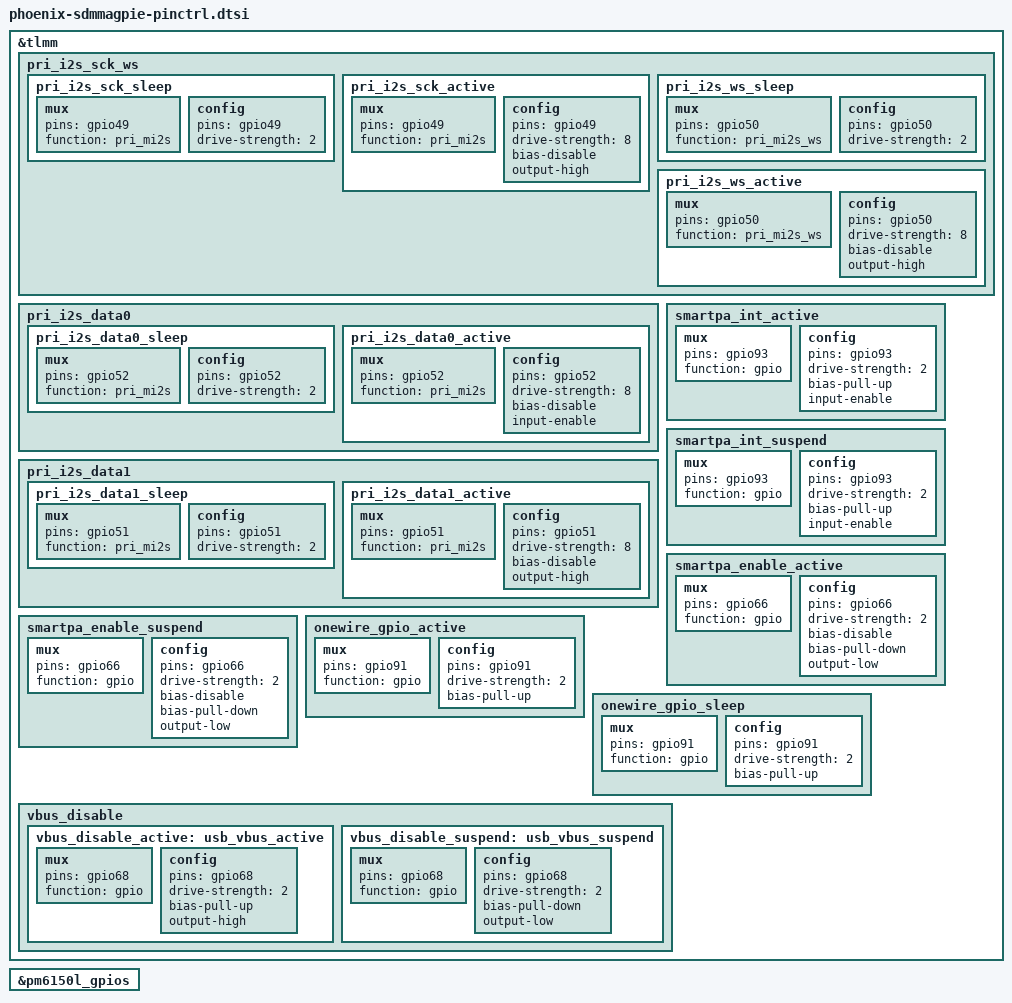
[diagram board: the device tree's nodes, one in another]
/*for G7B SM7150 pinctrl*/

&tlmm {

	pri_i2s_sck_ws {
		pri_i2s_sck_sleep: pri_i2s_sck_sleep {
			mux {
				pins = "gpio49";
				function = "pri_mi2s";
			};

			config {
				pins = "gpio49";
				drive-strength = <2>;   /* 2 mA */
			};
		};

		pri_i2s_sck_active: pri_i2s_sck_active {
			mux {
				pins = "gpio49";
				function = "pri_mi2s";
			};

			config {
				pins = "gpio49";
				drive-strength = <8>;   /* 8 mA */
				bias-disable;
				output-high;
			};
		};

		pri_i2s_ws_sleep: pri_i2s_ws_sleep {
			mux {
				pins = "gpio50";
				function = "pri_mi2s_ws";
			};

			config {
				pins = "gpio50";
				drive-strength = <2>;   /* 2 mA */
			};
		};

		pri_i2s_ws_active: pri_i2s_ws_active {
			mux {
				pins = "gpio50";
				function = "pri_mi2s_ws";
			};

			config {
				pins = "gpio50";
				drive-strength = <8>;   /* 8 mA */
				bias-disable;
				output-high;
			};
		};
	};

	pri_i2s_data0 {
		pri_i2s_data0_sleep: pri_i2s_data0_sleep {
			mux {
				pins = "gpio52";
				function = "pri_mi2s";
			};

			config {
				pins = "gpio52";
				drive-strength = <2>;   /* 2 mA */
			};
		};

		pri_i2s_data0_active: pri_i2s_data0_active {
			mux {
				pins = "gpio52";
				function = "pri_mi2s";
			};

			config {
				pins = "gpio52";
				drive-strength = <8>;   /* 8 mA */
				bias-disable;
				input-enable;
			};
		};
	};

	pri_i2s_data1 {
		pri_i2s_data1_sleep: pri_i2s_data1_sleep {
			mux {
				pins = "gpio51";
				function = "pri_mi2s";
			};

			config {
				pins = "gpio51";
				drive-strength = <2>;   /* 2 mA */
			};
		};

		pri_i2s_data1_active: pri_i2s_data1_active {
			mux {
				pins = "gpio51";
				function = "pri_mi2s";
			};

			config {
				pins = "gpio51";
				drive-strength = <8>;   /* 8 mA */
				bias-disable;
				output-high;
			};
		};
	};

	smartpa_int_active: smartpa_int_active {
		/* active state */
		mux {
			/* GPIO 93 Interrupt */
			pins = "gpio93";
			function = "gpio";
		};

		config {
			pins = "gpio93";
			drive-strength = <2>; /* 2 MA */
			bias-pull-up;
			input-enable;
		};
	};

	smartpa_int_suspend: smartpa_int_suspend {
		/* sleep state */
		mux {
			/* GPIO 93 Interrupt */
			pins = "gpio93";
			function = "gpio";
		};

		config {
			pins = "gpio93";
			drive-strength = <2>; /* 2 MA */
			bias-pull-up;
			input-enable;
		};
	};

	smartpa_enable_active: smartpa_enable_active {
		/* active state */
		mux {
			/* GPIO 66 rst pin */
			pins = "gpio66";
			function = "gpio";
		};

		config {
			pins = "gpio66";
			drive-strength = <2>;
			bias-disable;
			bias-pull-down;
			output-low;
		};
	};

	smartpa_enable_suspend: smartpa_enable_suspend {
		/* sleep state */
		mux {
			/* GPIO 66 rst pin */
			pins = "gpio66";
			function = "gpio";
		};

		config {
			pins = "gpio66";
			drive-strength = <2>;
			bias-disable;
			bias-pull-down;
			output-low;
		};
	};

	onewire_gpio_active: onewire_gpio_active {
		mux {
			pins = "gpio91";
			function = "gpio";
		};

		config {
			pins = "gpio91";
			drive-strength = <2>;
			bias-pull-up; /* No PULL */
		};
	};

	onewire_gpio_sleep: onewire_gpio_sleep {
		mux {
			pins = "gpio91";
			function = "gpio";
		};

		config {
			pins = "gpio91";
			drive-strength = <2>;
			bias-pull-up;
		};
	};

	vbus_disable {
		vbus_disable_active: usb_vbus_active {
			/* active state */
			mux {
				pins = "gpio68";
				function = "gpio";
			};

			config {
				pins = "gpio68";
				drive-strength = <2>; /* 2 MA */
				bias-pull-up;
				output-high;

			};
		};

		vbus_disable_suspend: usb_vbus_suspend {
			mux {
				pins = "gpio68";
				function = "gpio";
			};

			config {
				pins = "gpio68";
				drive-strength = <2>; /* 2 MA */
				bias-pull-down;
				output-low;
			};
		};
	};

};

&pm6150l_gpios {

};
